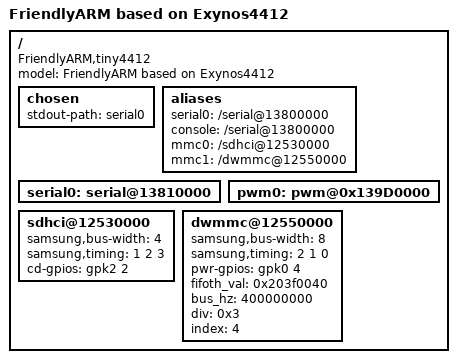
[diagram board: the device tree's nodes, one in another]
/*
 * Samsung's Exynos4412 based Trats2 board device tree source
 *
 * Copyright (c) 2014 Samsung Electronics Co., Ltd.
 *		http://www.samsung.com
 *
 * SPDX-License-Identifier:	GPL-2.0+
 */

/dts-v1/;
#include "exynos4412.dtsi"
#include "dt-bindings/gpio/gpio.h"
/ {
	model = "FriendlyARM  based on Exynos4412";
	compatible = "FriendlyARM,tiny4412", "samsung,exynos4412";

	chosen {
		stdout-path = "serial0";
	};
	aliases {
		serial0 = "/serial@13800000";
		console = "/serial@13800000";
		mmc0 = "/sdhci@12530000"; 		
		mmc1 = "/dwmmc@12550000";
	};

	serial0:serial@13810000{
			status = "okay";
		};
	pwm0:pwm@0x139D0000{

		 }

	sdhci@12530000 {
		samsung,bus-width = <4>;
		samsung,timing = <1 2 3>;
		cd-gpios = <&gpk2 2 0>;
	};

	dwmmc@12550000 {
		samsung,bus-width = <8>;
		samsung,timing = <2 1 0>;
		pwr-gpios = <&gpk0 4 0>;
		fifoth_val = <0x203f0040>;
		bus_hz = <400000000>;
		div = <0x3>;
		index = <4>;
	};
};
